# regs register map
Registers are 32-bit, access not given, no defined reset value unless marked. A register's access mark holds for its fields unless they carry their own. Addresses are absolute; registers are grouped by the start of their names; [hi:lo] are bit positions; {n}, {i} and the like mark numbered series.

## SC1
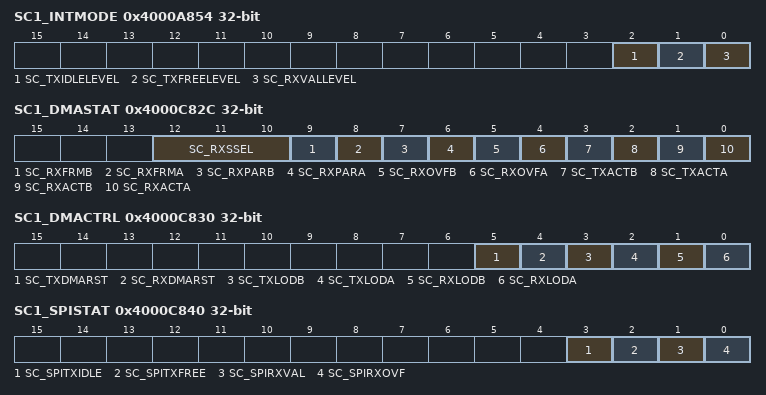
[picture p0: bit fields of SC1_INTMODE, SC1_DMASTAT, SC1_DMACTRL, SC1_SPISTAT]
0x4000A854 SC1_INTMODE
  [2] SC_TXIDLELEVEL, [1] SC_TXFREELEVEL, [0] SC_RXVALLEVEL
0x4000C800 SC1_RXBEGA
0x4000C804 SC1_RXENDA
0x4000C808 SC1_RXBEGB
0x4000C80C SC1_RXENDB
0x4000C810 SC1_TXBEGA
0x4000C814 SC1_TXENDA
0x4000C818 SC1_TXBEGB
0x4000C81C SC1_TXENDB
0x4000C820 SC1_RXCNTA
0x4000C824 SC1_RXCNTB
0x4000C828 SC1_TXCNT
0x4000C82C SC1_DMASTAT
  [12:10] SC_RXSSEL, [9] SC_RXFRMB, [8] SC_RXFRMA, [7] SC_RXPARB, [6] SC_RXPARA, [5] SC_RXOVFB, [4] SC_RXOVFA, [3] SC_TXACTB, [2] SC_TXACTA, [1] SC_RXACTB, [0] SC_RXACTA
0x4000C830 SC1_DMACTRL
  [5] SC_TXDMARST, [4] SC_RXDMARST, [3] SC_TXLODB, [2] SC_TXLODA, [1] SC_RXLODB, [0] SC_RXLODA
0x4000C834 SC1_RXERRA
0x4000C838 SC1_RXERRB
0x4000C83C SC1_DATA
0x4000C840 SC1_SPISTAT
  [3] SC_SPITXIDLE, [2] SC_SPITXFREE, [1] SC_SPIRXVAL, [0] SC_SPIRXOVF
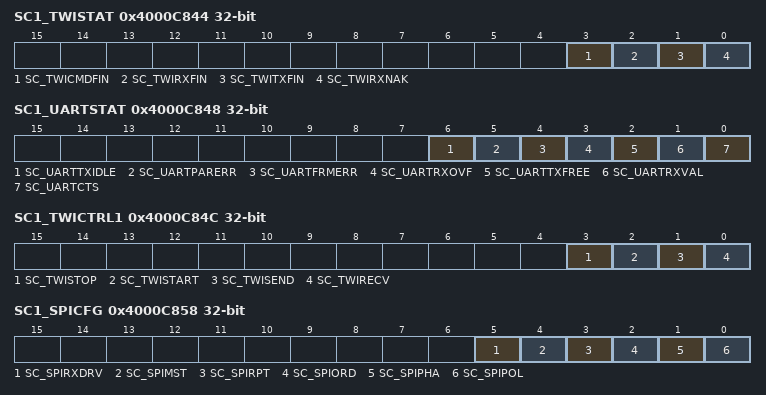
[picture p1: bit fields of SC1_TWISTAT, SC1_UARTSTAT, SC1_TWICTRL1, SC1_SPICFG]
0x4000C844 SC1_TWISTAT
  [3] SC_TWICMDFIN, [2] SC_TWIRXFIN, [1] SC_TWITXFIN, [0] SC_TWIRXNAK
0x4000C848 SC1_UARTSTAT
  [6] SC_UARTTXIDLE, [5] SC_UARTPARERR, [4] SC_UARTFRMERR, [3] SC_UARTRXOVF, [2] SC_UARTTXFREE, [1] SC_UARTRXVAL, [0] SC_UARTCTS
0x4000C84C SC1_TWICTRL1
  [3] SC_TWISTOP, [2] SC_TWISTART, [1] SC_TWISEND, [0] SC_TWIRECV
0x4000C850 SC1_TWICTRL2
0x4000C854 SC1_MODE
0x4000C858 SC1_SPICFG
  [5] SC_SPIRXDRV, [4] SC_SPIMST, [3] SC_SPIRPT, [2] SC_SPIORD, [1] SC_SPIPHA, [0] SC_SPIPOL
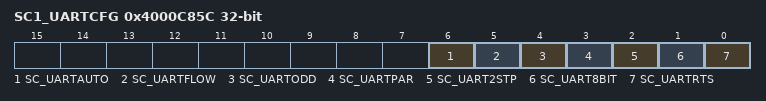
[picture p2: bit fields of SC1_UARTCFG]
0x4000C85C SC1_UARTCFG
  [6] SC_UARTAUTO, [5] SC_UARTFLOW, [4] SC_UARTODD, [3] SC_UARTPAR, [2] SC_UART2STP, [1] SC_UART8BIT, [0] SC_UARTRTS
0x4000C860 SC1_RATELIN
0x4000C864 SC1_RATEEXP
0x4000C868 SC1_UARTPER
0x4000C86C SC1_UARTFRAC
0x4000C870 SC1_RXCNTSAVED

## SC2
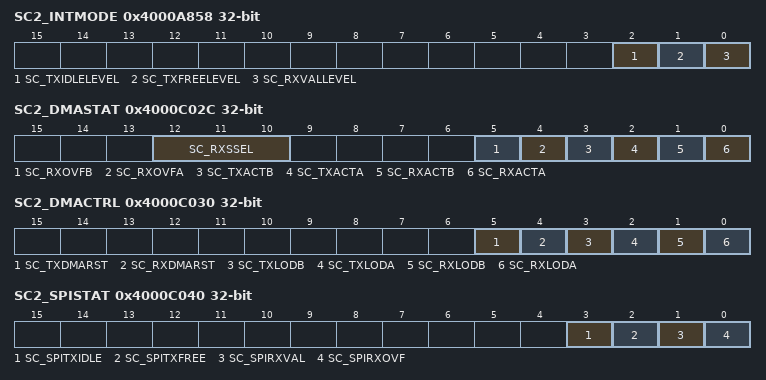
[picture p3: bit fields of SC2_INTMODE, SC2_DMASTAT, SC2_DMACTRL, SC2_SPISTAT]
0x4000A858 SC2_INTMODE
  [2] SC_TXIDLELEVEL, [1] SC_TXFREELEVEL, [0] SC_RXVALLEVEL
0x4000C000 SC2_RXBEGA
0x4000C004 SC2_RXENDA
0x4000C008 SC2_RXBEGB
0x4000C00C SC2_RXENDB
0x4000C010 SC2_TXBEGA
0x4000C014 SC2_TXENDA
0x4000C018 SC2_TXBEGB
0x4000C01C SC2_TXENDB
0x4000C020 SC2_RXCNTA
0x4000C024 SC2_RXCNTB
0x4000C028 SC2_TXCNT
0x4000C02C SC2_DMASTAT
  [12:10] SC_RXSSEL, [5] SC_RXOVFB, [4] SC_RXOVFA, [3] SC_TXACTB, [2] SC_TXACTA, [1] SC_RXACTB, [0] SC_RXACTA
0x4000C030 SC2_DMACTRL
  [5] SC_TXDMARST, [4] SC_RXDMARST, [3] SC_TXLODB, [2] SC_TXLODA, [1] SC_RXLODB, [0] SC_RXLODA
0x4000C034 SC2_RXERRA
0x4000C038 SC2_RXERRB
0x4000C03C SC2_DATA
0x4000C040 SC2_SPISTAT
  [3] SC_SPITXIDLE, [2] SC_SPITXFREE, [1] SC_SPIRXVAL, [0] SC_SPIRXOVF
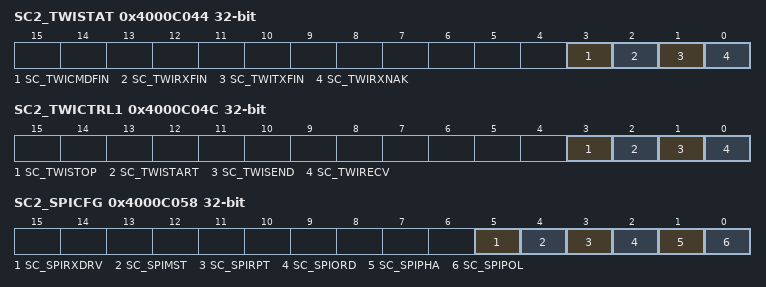
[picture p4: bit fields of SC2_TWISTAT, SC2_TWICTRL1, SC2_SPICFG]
0x4000C044 SC2_TWISTAT
  [3] SC_TWICMDFIN, [2] SC_TWIRXFIN, [1] SC_TWITXFIN, [0] SC_TWIRXNAK
0x4000C04C SC2_TWICTRL1
  [3] SC_TWISTOP, [2] SC_TWISTART, [1] SC_TWISEND, [0] SC_TWIRECV
0x4000C050 SC2_TWICTRL2
0x4000C054 SC2_MODE
0x4000C058 SC2_SPICFG
  [5] SC_SPIRXDRV, [4] SC_SPIMST, [3] SC_SPIRPT, [2] SC_SPIORD, [1] SC_SPIPHA, [0] SC_SPIPOL
0x4000C060 SC2_RATELIN
0x4000C064 SC2_RATEEXP
0x4000C070 SC2_RXCNTSAVED

## GPIO
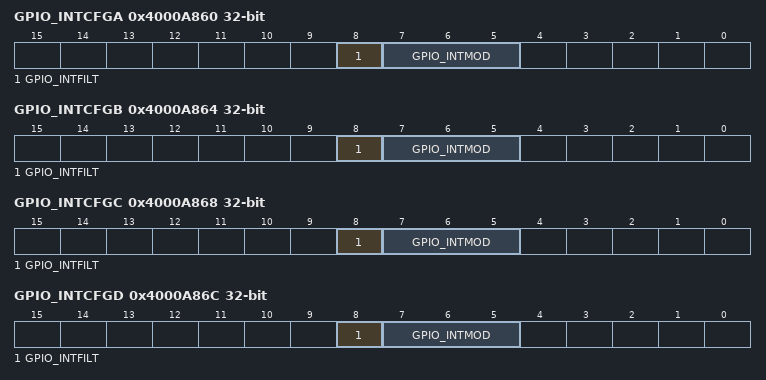
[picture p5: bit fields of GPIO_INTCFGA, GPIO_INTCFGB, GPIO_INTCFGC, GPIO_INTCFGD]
0x4000A860 GPIO_INTCFGA
  [8] GPIO_INTFILT, [7:5] GPIO_INTMOD
0x4000A864 GPIO_INTCFGB
  [8] GPIO_INTFILT, [7:5] GPIO_INTMOD
0x4000A868 GPIO_INTCFGC
  [8] GPIO_INTFILT, [7:5] GPIO_INTMOD
0x4000A86C GPIO_INTCFGD
  [8] GPIO_INTFILT, [7:5] GPIO_INTMOD
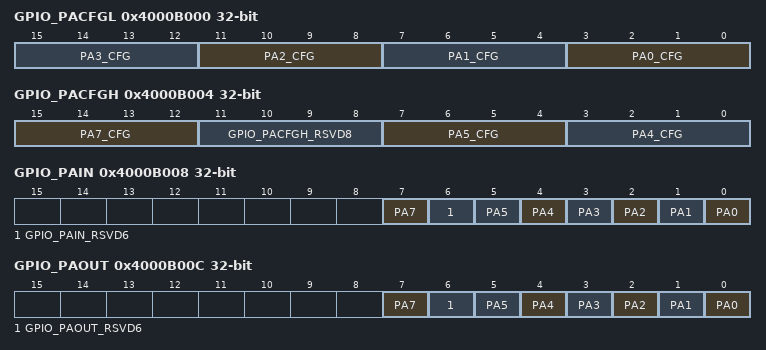
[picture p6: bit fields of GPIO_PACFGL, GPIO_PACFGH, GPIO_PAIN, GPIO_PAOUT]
0x4000B000 GPIO_PACFGL
  [4n+3:4n] PA{n}_CFG (n=0..3)
0x4000B004 GPIO_PACFGH
  [15:12] PA7_CFG, [11:8] GPIO_PACFGH_RSVD8, [7:4] PA5_CFG, [3:0] PA4_CFG
0x4000B008 GPIO_PAIN
  [7] PA7, [6] GPIO_PAIN_RSVD6, [n] PA{n} (n=0..5)
0x4000B00C GPIO_PAOUT
  [7] PA7, [6] GPIO_PAOUT_RSVD6, [n] PA{n} (n=0..5)
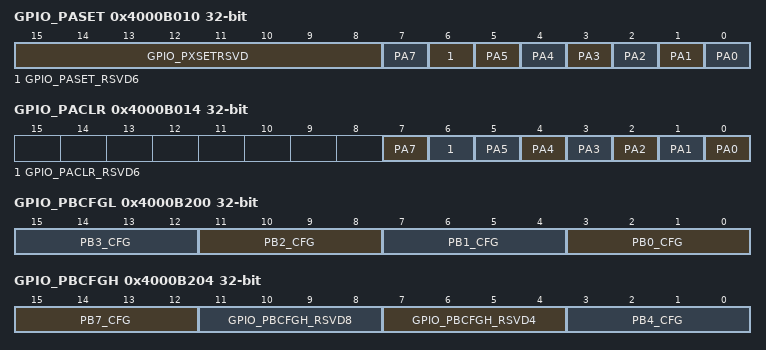
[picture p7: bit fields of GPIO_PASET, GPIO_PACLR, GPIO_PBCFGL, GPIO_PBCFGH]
0x4000B010 GPIO_PASET
  [15:8] GPIO_PXSETRSVD, [7] PA7, [6] GPIO_PASET_RSVD6, [n] PA{n} (n=0..5)
0x4000B014 GPIO_PACLR
  [7] PA7, [6] GPIO_PACLR_RSVD6, [n] PA{n} (n=0..5)
0x4000B200 GPIO_PBCFGL
  [4n+3:4n] PB{n}_CFG (n=0..3)
0x4000B204 GPIO_PBCFGH
  [15:12] PB7_CFG, [11:8] GPIO_PBCFGH_RSVD8, [7:4] GPIO_PBCFGH_RSVD4, [3:0] PB4_CFG
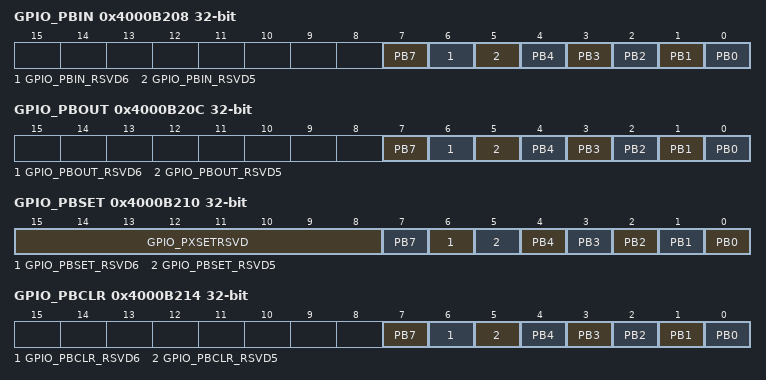
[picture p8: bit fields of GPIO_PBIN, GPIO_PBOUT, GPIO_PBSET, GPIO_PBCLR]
0x4000B208 GPIO_PBIN
  [7] PB7, [6] GPIO_PBIN_RSVD6, [5] GPIO_PBIN_RSVD5, [n] PB{n} (n=0..4)
0x4000B20C GPIO_PBOUT
  [7] PB7, [6] GPIO_PBOUT_RSVD6, [5] GPIO_PBOUT_RSVD5, [n] PB{n} (n=0..4)
0x4000B210 GPIO_PBSET
  [15:8] GPIO_PXSETRSVD, [7] PB7, [6] GPIO_PBSET_RSVD6, [5] GPIO_PBSET_RSVD5, [n] PB{n} (n=0..4)
0x4000B214 GPIO_PBCLR
  [7] PB7, [6] GPIO_PBCLR_RSVD6, [5] GPIO_PBCLR_RSVD5, [n] PB{n} (n=0..4)
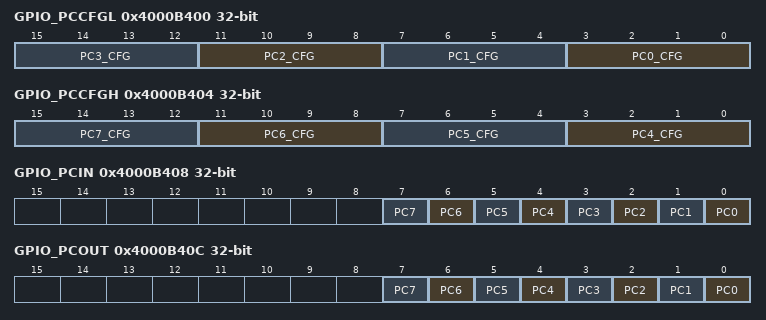
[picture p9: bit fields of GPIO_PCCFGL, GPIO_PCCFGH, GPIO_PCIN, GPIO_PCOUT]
0x4000B400 GPIO_PCCFGL
  [4n+3:4n] PC{n}_CFG (n=0..3)
0x4000B404 GPIO_PCCFGH
  [4n-13:4n-16] PC{n}_CFG (n=4..7)
0x4000B408 GPIO_PCIN
  [n] PC{n} (n=0..7)
0x4000B40C GPIO_PCOUT
  [n] PC{n} (n=0..7)
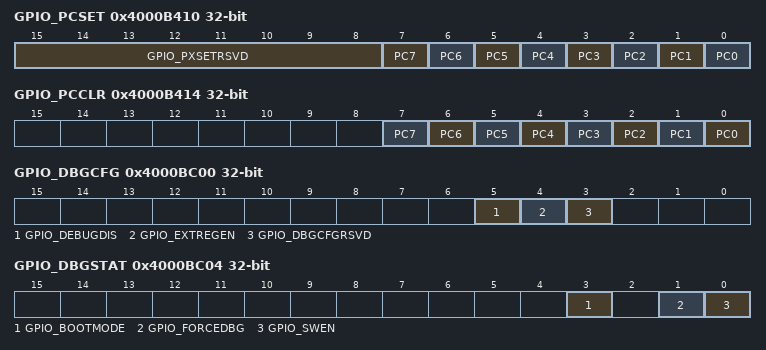
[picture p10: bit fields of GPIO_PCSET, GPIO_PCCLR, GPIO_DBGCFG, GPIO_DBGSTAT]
0x4000B410 GPIO_PCSET
  [15:8] GPIO_PXSETRSVD, [n] PC{n} (n=0..7)
0x4000B414 GPIO_PCCLR
  [n] PC{n} (n=0..7)
0x4000BC00 GPIO_DBGCFG
  [5] GPIO_DEBUGDIS, [4] GPIO_EXTREGEN, [3] GPIO_DBGCFGRSVD
0x4000BC04 GPIO_DBGSTAT
  [3] GPIO_BOOTMODE, [1] GPIO_FORCEDBG, [0] GPIO_SWEN
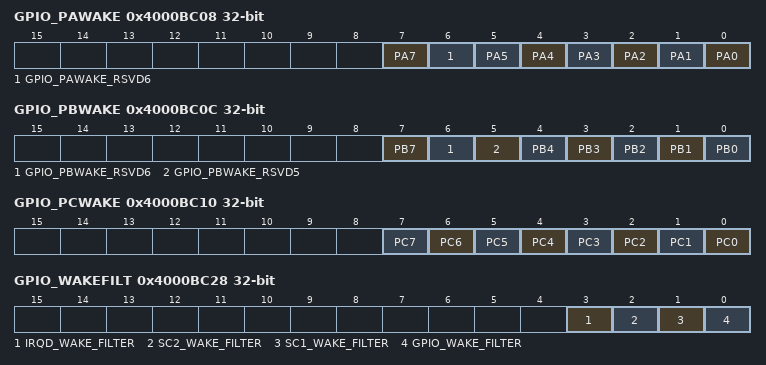
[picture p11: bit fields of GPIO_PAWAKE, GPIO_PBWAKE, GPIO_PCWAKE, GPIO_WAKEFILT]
0x4000BC08 GPIO_PAWAKE
  [7] PA7, [6] GPIO_PAWAKE_RSVD6, [n] PA{n} (n=0..5)
0x4000BC0C GPIO_PBWAKE
  [7] PB7, [6] GPIO_PBWAKE_RSVD6, [5] GPIO_PBWAKE_RSVD5, [n] PB{n} (n=0..4)
0x4000BC10 GPIO_PCWAKE
  [n] PC{n} (n=0..7)
0x4000BC20 GPIO_IRQCSEL
0x4000BC24 GPIO_IRQDSEL
0x4000BC28 GPIO_WAKEFILT
  [3] IRQD_WAKE_FILTER, [2] SC2_WAKE_FILTER, [1] SC1_WAKE_FILTER, [0] GPIO_WAKE_FILTER

## ADC
0x4000E000 ADC_DATA
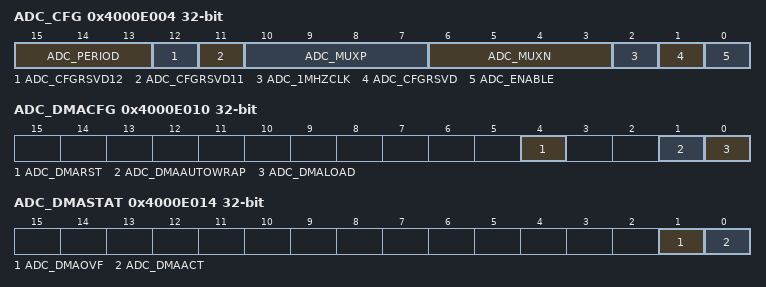
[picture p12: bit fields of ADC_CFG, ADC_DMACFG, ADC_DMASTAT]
0x4000E004 ADC_CFG
  [15:13] ADC_PERIOD, [12] ADC_CFGRSVD12, [11] ADC_CFGRSVD11, [10:7] ADC_MUXP, [6:3] ADC_MUXN, [2] ADC_1MHZCLK, [1] ADC_CFGRSVD, [0] ADC_ENABLE
0x4000E008 ADC_OFFSET
0x4000E00C ADC_GAIN
0x4000E010 ADC_DMACFG
  [4] ADC_DMARST, [1] ADC_DMAAUTOWRAP, [0] ADC_DMALOAD
0x4000E014 ADC_DMASTAT
  [1] ADC_DMAOVF, [0] ADC_DMAACT
0x4000E018 ADC_DMABEG
0x4000E01C ADC_DMASIZE
0x4000E020 ADC_DMACUR
0x4000E024 ADC_DMACNT

## TIM1
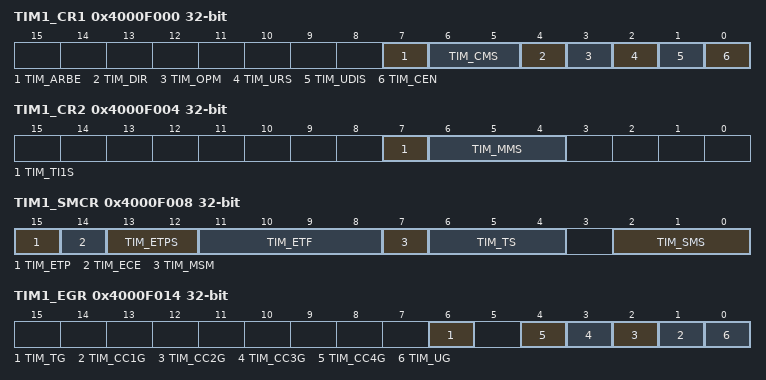
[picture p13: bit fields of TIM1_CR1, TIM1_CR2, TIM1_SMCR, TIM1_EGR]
0x4000F000 TIM1_CR1
  [7] TIM_ARBE, [6:5] TIM_CMS, [4] TIM_DIR, [3] TIM_OPM, [2] TIM_URS, [1] TIM_UDIS, [0] TIM_CEN
0x4000F004 TIM1_CR2
  [7] TIM_TI1S, [6:4] TIM_MMS
0x4000F008 TIM1_SMCR
  [15] TIM_ETP, [14] TIM_ECE, [13:12] TIM_ETPS, [11:8] TIM_ETF, [7] TIM_MSM, [6:4] TIM_TS, [2:0] TIM_SMS
0x4000F014 TIM1_EGR
  [6] TIM_TG, [n] TIM_CC{n}G (n=1..4), [0] TIM_UG
0x4000F018 TIM1_CCMR1
  [15] TIM_OC2CE, [15:12] TIM_IC2F, [14:12] TIM_OC2M, [11] TIM_OC2BE, [11:10] TIM_IC2PSC, [10] TIM_OC2FE, [9:8] TIM_CC2S, [7] TIM_OC1CE, [7:4] TIM_IC1F, [6:4] TIM_OC1M, [3] TIM_OC1PE, [3:2] TIM_IC1PSC, [2] TIM_OC1FE, [1:0] TIM_CC1S
0x4000F01C TIM1_CCMR2
  [15] TIM_OC4CE, [15:12] TIM_IC4F, [14:12] TIM_OC4M, [11] TIM_OC4BE, [11:10] TIM_IC4PSC, [10] TIM_OC4FE, [9:8] TIM_CC4S, [7] TIM_OC3CE, [7:4] TIM_IC3F, [6:4] TIM_OC3M, [3] TIM_OC3BE, [3:2] TIM_IC3PSC, [2] TIM_OC3FE, [1:0] TIM_CC3S
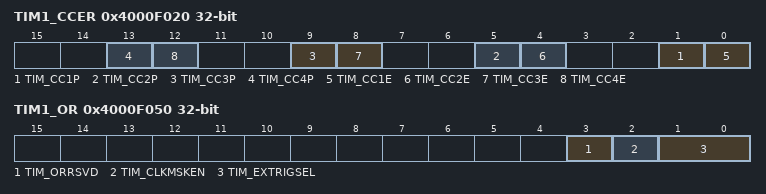
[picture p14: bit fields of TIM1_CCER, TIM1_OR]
0x4000F020 TIM1_CCER
  [4n-3] TIM_CC{n}P (n=1..4), [4n-4] TIM_CC{n}E (n=1..4)
0x4000F024 TIM1_CNT
0x4000F028 TIM1_PSC
0x4000F02C TIM1_ARR
{0x4000F030+4i} TIM1_CCR{i} (i=1..4)
0x4000F050 TIM1_OR
  [3] TIM_ORRSVD, [2] TIM_CLKMSKEN, [1:0] TIM_EXTRIGSEL

## TIM2
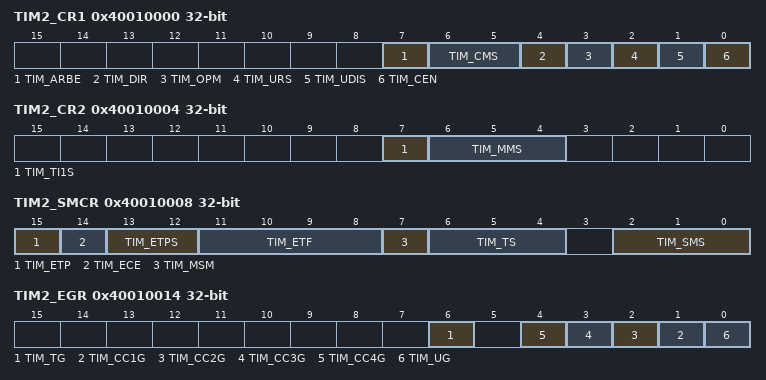
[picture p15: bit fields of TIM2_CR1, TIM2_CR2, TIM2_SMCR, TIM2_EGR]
0x40010000 TIM2_CR1
  [7] TIM_ARBE, [6:5] TIM_CMS, [4] TIM_DIR, [3] TIM_OPM, [2] TIM_URS, [1] TIM_UDIS, [0] TIM_CEN
0x40010004 TIM2_CR2
  [7] TIM_TI1S, [6:4] TIM_MMS
0x40010008 TIM2_SMCR
  [15] TIM_ETP, [14] TIM_ECE, [13:12] TIM_ETPS, [11:8] TIM_ETF, [7] TIM_MSM, [6:4] TIM_TS, [2:0] TIM_SMS
0x40010014 TIM2_EGR
  [6] TIM_TG, [n] TIM_CC{n}G (n=1..4), [0] TIM_UG
0x40010018 TIM2_CCMR1
  [15] TIM_OC2CE, [15:12] TIM_IC2F, [14:12] TIM_OC2M, [11] TIM_OC2BE, [11:10] TIM_IC2PSC, [10] TIM_OC2FE, [9:8] TIM_CC2S, [7] TIM_OC1CE, [7:4] TIM_IC1F, [6:4] TIM_OC1M, [3] TIM_OC1PE, [3:2] TIM_IC1PSC, [2] TIM_OC1FE, [1:0] TIM_CC1S
0x4001001C TIM2_CCMR2
  [15] TIM_OC4CE, [15:12] TIM_IC4F, [14:12] TIM_OC4M, [11] TIM_OC4BE, [11:10] TIM_IC4PSC, [10] TIM_OC4FE, [9:8] TIM_CC4S, [7] TIM_OC3CE, [7:4] TIM_IC3F, [6:4] TIM_OC3M, [3] TIM_OC3BE, [3:2] TIM_IC3PSC, [2] TIM_OC3FE, [1:0] TIM_CC3S
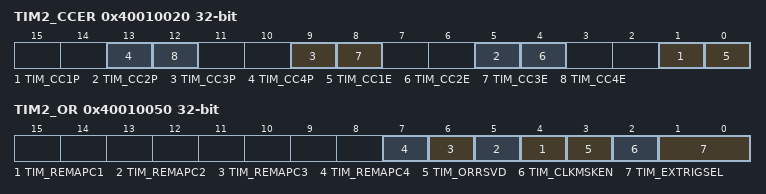
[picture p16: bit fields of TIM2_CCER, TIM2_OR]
0x40010020 TIM2_CCER
  [4n-3] TIM_CC{n}P (n=1..4), [4n-4] TIM_CC{n}E (n=1..4)
0x40010024 TIM2_CNT
0x40010028 TIM2_PSC
0x4001002C TIM2_ARR
{0x40010030+4i} TIM2_CCR{i} (i=1..4)
0x40010050 TIM2_OR
  [n+3] TIM_REMAPC{n} (n=1..4), [3] TIM_ORRSVD, [2] TIM_CLKMSKEN, [1:0] TIM_EXTRIGSEL

## SFR
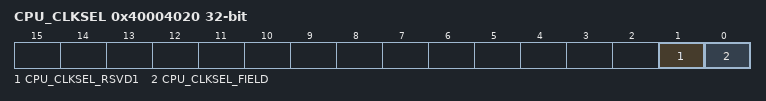
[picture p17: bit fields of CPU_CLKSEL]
0x40004020 CPU_CLKSEL
  [1] CPU_CLKSEL_RSVD1, [0] CPU_CLKSEL_FIELD
0x40004038 PERIPHERAL_DISABLE
  [8] PERIPHERAL_DISABLE_RSVD8, [7] PERIPHERAL_DISABLE_RSVD7, [6] PERIPHERAL_DISABLE_RSVD6, [5] PERIDIS_RSVD, [4] PERIDIS_ADC, [3] PERIDIS_TIM2, [2] PERIDIS_TIM1, [1] PERIDIS_SC1, [0] PERIDIS_SC2
0x4000403C RAM_RETAIN
0xE000ED3C SCS_AFSR
  [3] WRONGSIZE, [2] PROTECTED, [0] MISSED

## Notices in the file
Copyright 2015 Silicon Laboratories, Inc.
